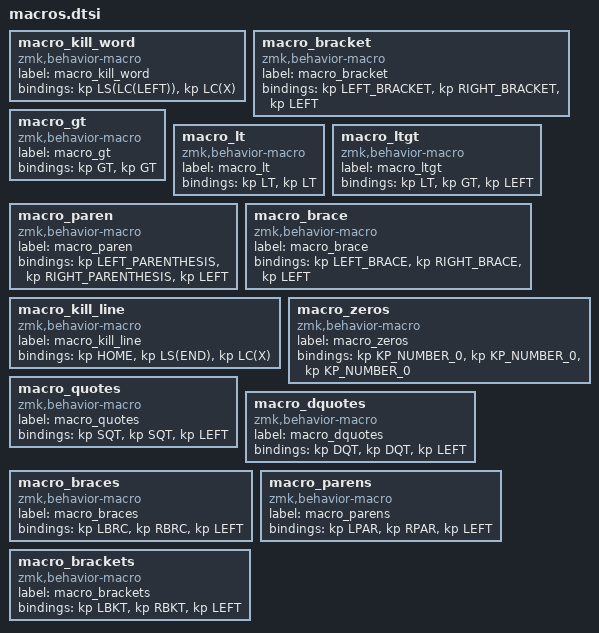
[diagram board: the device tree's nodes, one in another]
macro_kill_word: macro_kill_word{
compatible = "zmk,behavior-macro";
label = "macro_kill_word";
#binding-cells = <0>;
bindings = <&kp LS(LC(LEFT))>, <&kp LC(X)>;
};
macro_bracket: macro_bracket{
compatible = "zmk,behavior-macro";
label = "macro_bracket";
#binding-cells = <0>;
bindings = <&kp LEFT_BRACKET>, <&kp RIGHT_BRACKET>, <&kp LEFT>;
};
macro_gt: macro_gt{
compatible = "zmk,behavior-macro";
label = "macro_gt";
#binding-cells = <0>;
bindings = <&kp GT>, <&kp GT>;
};
macro_lt: macro_lt{
compatible = "zmk,behavior-macro";
label = "macro_lt";
#binding-cells = <0>;
bindings = <&kp LT>, <&kp LT>;
};
macro_ltgt: macro_ltgt{
compatible = "zmk,behavior-macro";
label = "macro_ltgt";
#binding-cells = <0>;
bindings = <&kp LT>, <&kp GT>, <&kp LEFT>;
};
macro_paren: macro_paren{
compatible = "zmk,behavior-macro";
label = "macro_paren";
#binding-cells = <0>;
bindings = <&kp LEFT_PARENTHESIS>, <&kp RIGHT_PARENTHESIS>, <&kp LEFT>;
};
macro_brace: macro_brace{
compatible = "zmk,behavior-macro";
label = "macro_brace";
#binding-cells = <0>;
bindings = <&kp LEFT_BRACE>, <&kp RIGHT_BRACE>, <&kp LEFT>;
};
macro_kill_line: macro_kill_line{
compatible = "zmk,behavior-macro";
label = "macro_kill_line";
#binding-cells = <0>;
bindings = <&kp HOME>, <&kp LS(END)>, <&kp LC(X)>;
};
macro_zeros: macro_zeros{
compatible = "zmk,behavior-macro";
label = "macro_zeros";
#binding-cells = <0>;
bindings = <&kp KP_NUMBER_0>, <&kp KP_NUMBER_0>, <&kp KP_NUMBER_0>;
};
macro_quotes: macro_quotes{
compatible = "zmk,behavior-macro";
label = "macro_quotes";
#binding-cells = <0>;
bindings = <&kp SQT>, <&kp SQT>, <&kp LEFT>;
};
macro_dquotes: macro_dquotes{
compatible = "zmk,behavior-macro";
label = "macro_dquotes";
#binding-cells = <0>;
bindings = <&kp DQT>, <&kp DQT>, <&kp LEFT>;
};
macro_braces: macro_braces{
compatible = "zmk,behavior-macro";
label = "macro_braces";
#binding-cells = <0>;
bindings = <&kp LBRC>, <&kp RBRC>, <&kp LEFT>;
};
macro_parens: macro_parens{
compatible = "zmk,behavior-macro";
label = "macro_parens";
#binding-cells = <0>;
bindings = <&kp LPAR>, <&kp RPAR>, <&kp LEFT>;
};
macro_brackets: macro_brackets{
compatible = "zmk,behavior-macro";
label = "macro_brackets";
#binding-cells = <0>;
bindings = <&kp LBKT>, <&kp RBKT>, <&kp LEFT>;
};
